# nrf7140_application register map
Vendor: Nordic Semiconductor; Series: nRF71; File version: 1
CPU: CM33 r0p4, little endian, MPU, FPU, 3 interrupt priority bits, 480 interrupts, 8 SAU regions
Registers are 32-bit, read-write, reset 0x0 unless marked. A register's access mark holds for its fields unless they carry their own. Offsets are from the block's base; [hi:lo] are bit positions; lines under a group give offsets from that group; {n}, {i} and the like mark numbered series; 'fields as' and 'values as' point back to an identical list.

## GLOBAL_VREGGFX_NS — VREGVS0V8 peripheral
Base 0x49012000
0x100 EVENTS_READY — Power up done
  [0] EVENTS_READY
    0=NotGenerated (Event not generated); 1=Generated (Event generated)
0x104 EVENTS_SETTLED — Settled flag for MODE handshake
  [0] EVENTS_SETTLED
    values as EVENTS_READY.EVENTS_READY
0x108 EVENTS_IOUTCMP — Analog current comparator
  [0] EVENTS_IOUTCMP
    values as EVENTS_READY.EVENTS_READY
0x10C EVENTS_LP2HP — Current consumption above threshold
  [0] EVENTS_LP2HP
    values as EVENTS_READY.EVENTS_READY
0x110 EVENTS_HP2LP — Current consumption below threshold
  [0] EVENTS_HP2LP
    values as EVENTS_READY.EVENTS_READY
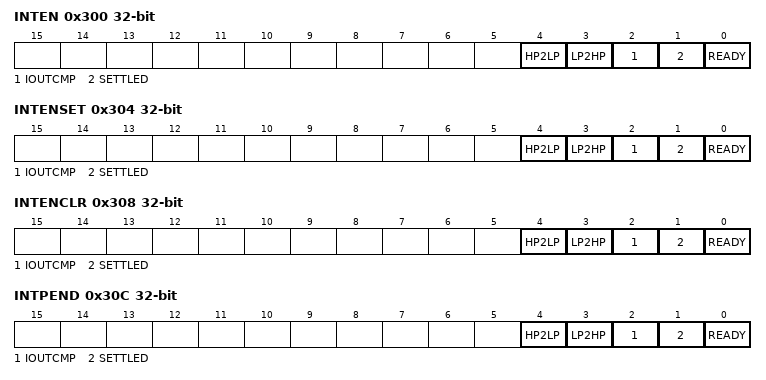
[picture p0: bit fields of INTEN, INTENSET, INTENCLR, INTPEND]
0x300 INTEN — Enable or disable interrupt
  [all] fields
    0=Disabled; 1=Enabled
  [4] HP2LP — Enable or disable interrupt for event HP2LP
  [3] LP2HP — Enable or disable interrupt for event LP2HP
  [2] IOUTCMP — Enable or disable interrupt for event IOUTCMP
  [1] SETTLED — Enable or disable interrupt for event SETTLED
  [0] READY — Enable or disable interrupt for event READY
0x304 INTENSET — Enable interrupt
  [all] fields
    on read: 0=Disabled (Read: Disabled); 1=Enabled (Read: Enabled) | on write: 1=Set (Enable)
  [4] HP2LP — Write '1' to enable interrupt for event HP2LP
  [3] LP2HP — Write '1' to enable interrupt for event LP2HP
  [2] IOUTCMP — Write '1' to enable interrupt for event IOUTCMP
  [1] SETTLED — Write '1' to enable interrupt for event SETTLED
  [0] READY — Write '1' to enable interrupt for event READY
0x308 INTENCLR — Disable interrupt
  [all] fields
    on read: 0=Disabled (Read: Disabled); 1=Enabled (Read: Enabled) | on write: 1=Clear (Disable)
  [4] HP2LP — Write '1' to disable interrupt for event HP2LP
  [3] LP2HP — Write '1' to disable interrupt for event LP2HP
  [2] IOUTCMP — Write '1' to disable interrupt for event IOUTCMP
  [1] SETTLED — Write '1' to disable interrupt for event SETTLED
  [0] READY — Write '1' to disable interrupt for event READY
0x30C INTPEND ro — Pending interrupts
  [all] fields
    on read: 0=NotPending (Read: Not pending); 1=Pending (Read: Pending)
  [4] HP2LP — Read pending status of interrupt for event HP2LP
  [3] LP2HP — Read pending status of interrupt for event LP2HP
  [2] IOUTCMP — Read pending status of interrupt for event IOUTCMP
  [1] SETTLED — Read pending status of interrupt for event SETTLED
  [0] READY — Read pending status of interrupt for event READY
0x400 STATUS ro — Voltage regulator status
  [1:0] MODE — Current voltage regulator mode
    0=High power mode; 1=Low power mode; 2=Ultra-low power refresh mode
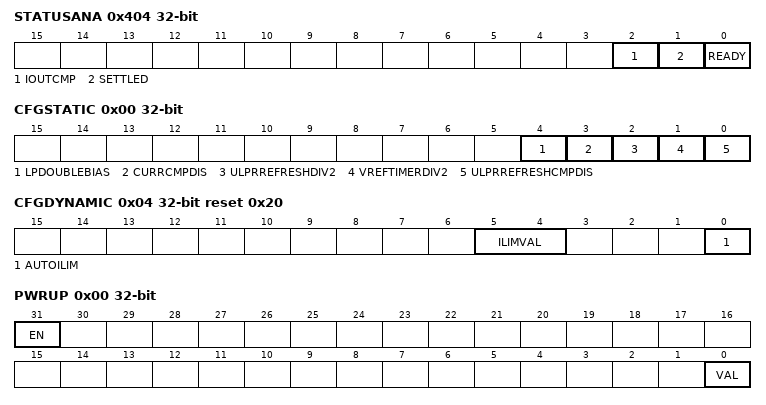
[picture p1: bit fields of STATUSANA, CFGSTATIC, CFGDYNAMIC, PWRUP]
0x404 STATUSANA ro — Status of analog module output signals
  [2] IOUTCMP — Current value of the IOUTCMP signal from the analog module
  [1] SETTLED — Current value of the SETTLED signal from the analog module
  [0] READY — Current value of the READY signal from the analog module
0x410 CONFIG group — Unspecified
  0x00 CFGSTATIC — Voltage regulator static CFG configuration
    [all] fields
      0=Disabled (Configuration disabled); 1=Enabled (Configuration enabled)
    [4] LPDOUBLEBIAS — Double the LP core bias current
    [3] CURRCMPDIS — Disable the current comparator
    [2] ULPRREFRESHDIV2 — Divide the ULPR refresh timer by 2
    [1] VREFTIMERDIV2 — Divide the VREF timer by 2
    [0] ULPRREFRESHCMPDIS — Disable the ULPR refresh comparator
  0x04 CFGDYNAMIC reset 0x20 — Voltage regulator dynamic CFG configuration
    [5:4] ILIMVAL — Current limit configuration
      0=Normal operation; 1=IlimHigh (High soft start limit); 2=IlimMid (WU soft start); 3=IlimLow (Reset current limit)
    [0] AUTOILIM — Current limit auto mode
      0=Disabled (Auto mode disabled); 1=Enabled (Auto mode enabled)
0x440 TRIM group — Unspecified
  0x00 IREF reset 0x8 — Local current reference trimming
    [6:0] VAL — Current reference trimming value
  0x04 HIGHPOWER — High power mode output voltage offset trimming
    [3:0] VAL — Voltage offset trimming value
  0x08 LOWPOWER — Low power mode output voltage offset trimming
    [3:0] VAL — Voltage offset trimming value.
  0x0C ULPR — ULPR mode comparator offset trimming
    [2:0] VAL — Comparator offset trimming value.
0x480 MIRROR reset 0x1 — Enable LOCK for mirrored registers
  [0] LOCK — Lock for mirrored registers
    0=Disabled (Lock disabled); 1=Enabled (Lock enabled)
0x484 VOUTHP reset 0x30 — High power mode output voltage programming
  [5:0] VAL — Output voltage value
0x488 VOUTLP reset 0x30 — Low power mode output voltage programming
  [5:0] VAL — Output voltage value
0x48C MODE — Voltage regulator mode
  [1:0] MODE
    0=Automatically handled by the peripheral; 1=High power mode; 2=Low power mode; 3=Ultra-low power refresh mode
0x490 ITHRESHOLD reset 0xA — Current threshold for mode transistion
  [3:0] VAL — Current consumption
0x494 VOUTHPHELPER reset 0x2C — High power helper mode output voltage programming
  [5:0] VAL — Output voltage value
0x500 OVERRIDE group — Unspecified
  0x00 PWRUP — Override the PWRUP signal to the analog module
    [31] EN — Enable the override
      0=Disabled (Override is disabled); 1=Enabled (Override is enabled)
    [0] VAL — Override value for the signal
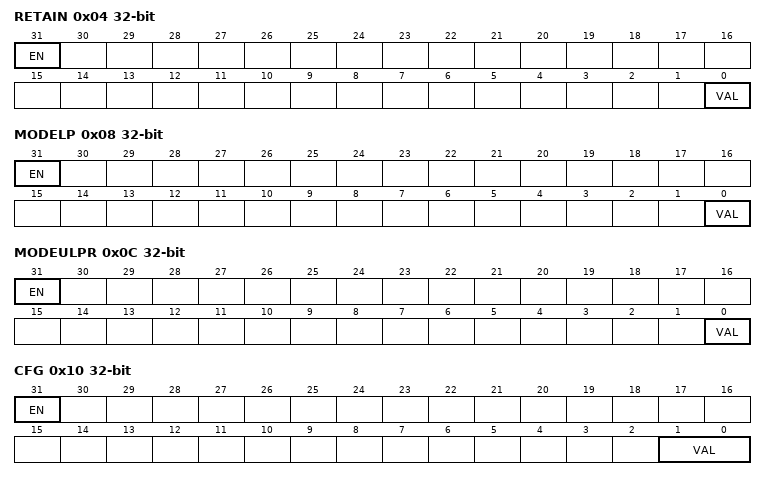
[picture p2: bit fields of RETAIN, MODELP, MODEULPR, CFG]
  0x04 RETAIN — Override the RETAIN signal to the analog module
    fields as OVERRIDE.PWRUP
  0x08 MODELP — Override the MODE LP signal to the analog module
    fields as OVERRIDE.PWRUP
  0x0C MODEULPR — Override the MODE ULPR signal to the analog module
    fields as OVERRIDE.PWRUP
  0x10 CFG — Override the dynamic CFG signal to the analog module
    [31] EN — Enable the override
      values as OVERRIDE.PWRUP.EN
    [1:0] VAL — Override value for the signal
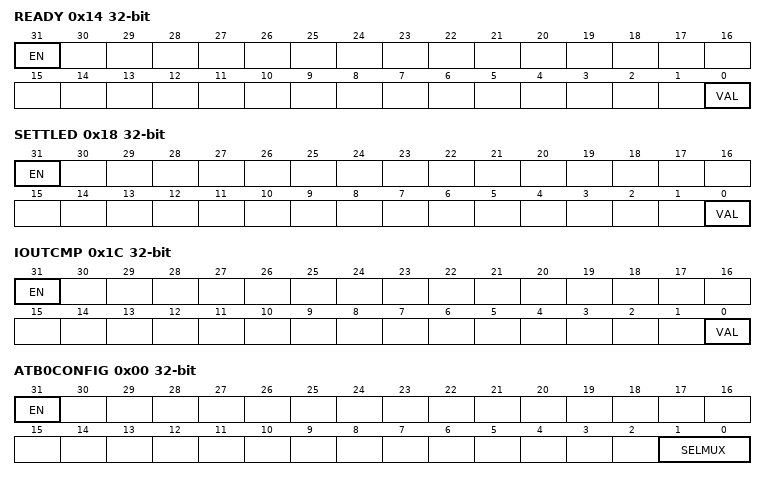
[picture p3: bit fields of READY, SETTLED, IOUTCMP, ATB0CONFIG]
  0x14 READY — Override the READY signal from the analog module
    [31] EN — Enable the override
      values as OVERRIDE.PWRUP.EN
    [0] VAL — Current value of the signal
  0x18 SETTLED — Override the SETTLED signal from the analog module
    fields as OVERRIDE.READY
  0x1C IOUTCMP — Override the IOUTCMP signal from the analog module
    fields as OVERRIDE.READY
0x600 DFT group — Unspecified
  0x00 ATB0CONFIG — Analog Test Bus 0 (ATB0) configuration
    [31] EN — Enable the analog test bus
      0=Disabled (Analog test bus is disabled); 1=Enabled (Analog test bus is enabled)
    [1:0] SELMUX — Select multiplexer for ATB0
      0=ExtVref (Negative input of calibration comparator); 1=Ibpp50n (Internal 50nA current reference); 2=Ibpsr4u (Internal 4uA current reference); 3=Ibpp50nIbpsr4u (Sum both internal current references)
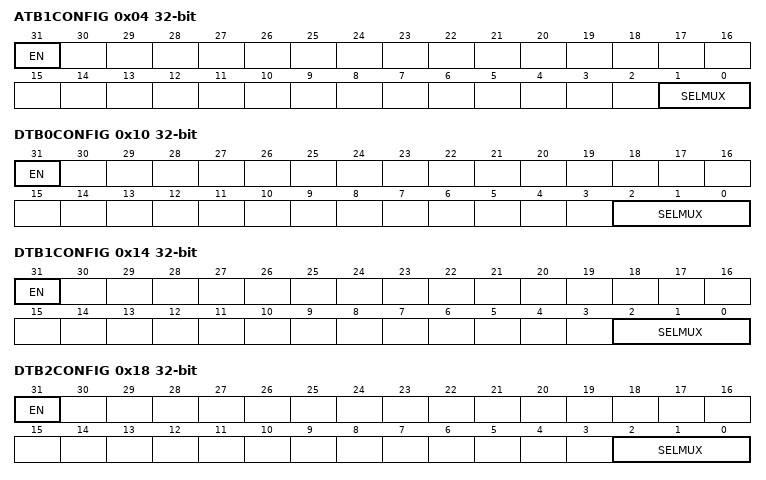
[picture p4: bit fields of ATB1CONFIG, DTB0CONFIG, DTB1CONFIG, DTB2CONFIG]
  0x04 ATB1CONFIG — Analog Test Bus 1 (ATB1) configuration
    [31] EN — Enable the analog test bus
      values as DFT.ATB0CONFIG.EN
    [1:0] SELMUX — Select multiplexer for ATB1
      0=VSS; 1=BufferedHPvref; 2=VDDVS0V8; 3=Ibpsr4u (Internal 4uA current reference, through 225kOhm resistor)
  0x10 DTB0CONFIG — Digital Test Bus 0 (DTB0) configuration
    [31] EN — Enable the digital test bus
      0=Disabled (Digital test bus is disabled); 1=Enabled (Digital test bus is enabled)
    [2:0] SELMUX — Select multiplexer for DTB0
      0=Spare0 (None selected, logic 0); 1=RefreshULPR (ULPR refresh pulse); 2=SettledIBPSR (BIAS_IBPSR_4U_DVT settled signal); 3=Spare1 (None selected, logic 0); 4=CurrCmp (Current comparator output); 5=ReqModeLP (LP mode request); 6=RegModeULPR (ULPR mode request); 7=CalCmp (Calibration comparator output)
  0x14 DTB1CONFIG — Digital Test Bus 1 (DTB1) configuration
    [31] EN — Enable the digital test bus
      values as DFT.DTB0CONFIG.EN
    [2:0] SELMUX — Select multiplexer for DTB1
      0=Vref timer acknowledge; 1=RefreshTimerAck (ULPR refresh timer acknowledge); 2=ReadyIBPSR (IBPSR ready signal); 3=ReadyHP (High power core ready signal); 4=ReadyLP (Low power core ready signal); 5=CancelLPAck (Low power core cancel acknowledge signal); 6=ReadyIBPP5n (BIAS_IBPP_5N ready signal); 7=Settled signal
  0x18 DTB2CONFIG — Digital Test Bus 2 (DTB2) configuration
    [31] EN — Enable the digital test bus
      values as DFT.DTB0CONFIG.EN
    [2:0] SELMUX — Select multiplexer for DTB2
      0=Vref timer request; 1=RefreshTimerReq (ULPR refresh timer request); 2=PwrupIBPSR (IBPSR power up signal); 3=PwrupHP (High power core power up signal); 4=PwrupLP (Low power core power up signal); 5=CancelLP (Low power core cancel signal); 6=PwrupIBPP5n (BIAS_IBPP_5N power up signal); 7=Spare0 (None selected, logic 0)
  0x1C DTB3CONFIG — Digital Test Bus 3 (DTB3) configuration
    [27] PWRUPDELTEST — Enable the PWRUP delay test circuit
      0=Disabled (PWRUP delay test circuit is disabled); 1=Enabled (PWRUP delay test circuit is enabled)
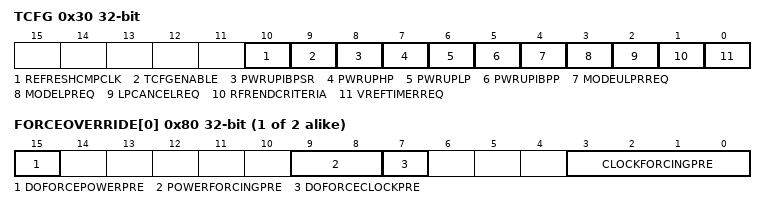
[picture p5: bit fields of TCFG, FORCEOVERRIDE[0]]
  0x30 TCFG — Test mode configuration
    [10] REFRESHCMPCLK — Controls clock input of refresh comparator
    [9] TCFGENABLE — Enable TCFG control
    [8] PWRUPIBPSR — Controls PWRUP_IBPSR_BIAS_SW_1V8
    [7] PWRUPHP — Controls PWRUP_LDO_HP_AO_1V8
    [6] PWRUPLP — Controls PWRUP_LDO_LP_AO_1V8
    [5] PWRUPIBPP — Controls PWRUP_IBPP_BIAS_SW_1V8
    [4] MODEULPRREQ — Controls MODE_ULPR_REQ_SW_1V8
    [3] MODELPREQ — Controls MODE_LP_REQ_SW_1V8
    [2] LPCANCELREQ — Controls LDP_LP_CANCEL_REQ_AO_1V8
    [1] RFRENDCRITERIA — Controls RFR_END_CRITERIA_REQ_SW_1V8
    [0] VREFTIMERREQ — Controls VREF_TIMER_REQ_SW_1V8
  0x34 CALEN — Calibration enable
    [0] CALEN
      0=ATCMPOff; 1=ATCMPOn
  0x38 CALCMP ro — Calibration compare
    [0] CALCMP
0xF00 PCGCSLAVE group — Unspecified
  {0x0+4j} PENALTY[{j}] (j=0..1) reset 0xFFFFFFFC — Description collection: Penalty level for power/clock pair n. When FULL_PCP_ZERO feature is not supported, PENALTY[0] address overlaps the PENALTY0 address and register description for PENALTY[0] is not valid.
    [1:0] PENALTY — Penalty level
  {0x80+4j} FORCEOVERRIDE[{j}] (j=0..1) — Description collection: Force override of power/clock pair n.
    [15] DOFORCEPOWERPRE, [9:8] POWERFORCINGPRE, [7] DOFORCECLOCKPRE, [3:0] CLOCKFORCINGPRE
